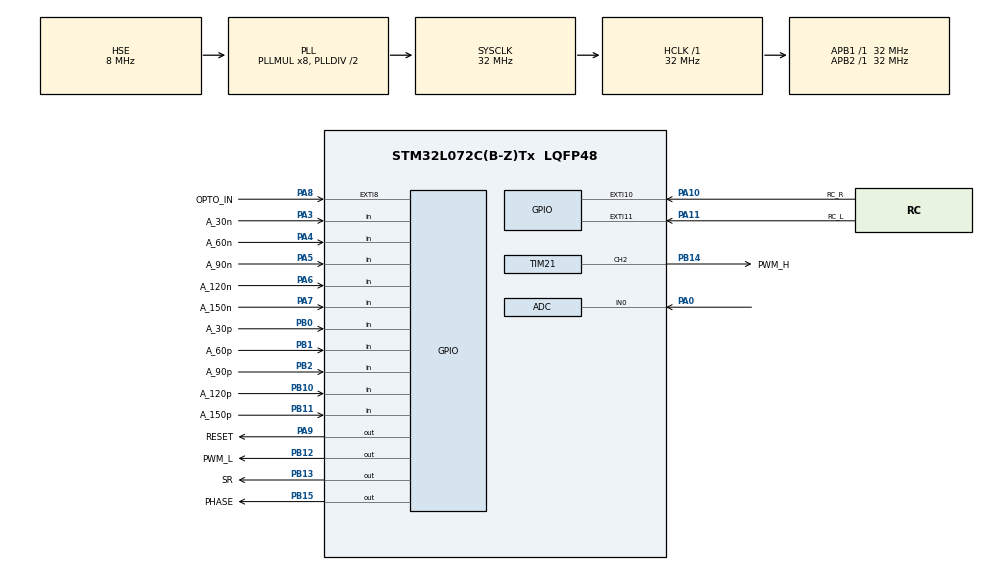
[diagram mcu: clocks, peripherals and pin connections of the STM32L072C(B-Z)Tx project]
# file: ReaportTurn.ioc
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Mcu.Family=STM32L0
PH0-OSC_IN.Signal=RCC_OSC_IN
Dma.ADC.0.Mode=DMA_CIRCULAR
PB10.GPIO_PuPd=GPIO_PULLDOWN
PB14.GPIO_Label=PWM_H
PA3.GPIO_PuPd=GPIO_PULLDOWN
Dma.ADC.0.Priority=DMA_PRIORITY_LOW
PB0.GPIO_Label=A_30p
PA6.GPIO_Label=A_120n
PB11.GPIO_PuPd=GPIO_PULLDOWN
PB13.GPIO_Label=SR
PB11.Signal=GPIO_Input
PB13.Signal=GPIO_Output
PB15.Signal=GPIO_Output
RCC.SYSCLKSource=RCC_SYSCLKSOURCE_PLLCLK
ProjectManager.StackSize=0x400
VP_TIM7_VS_ClockSourceINT.Mode=Enable_Timer
ADC.DiscontinuousConvMode=ENABLE
TIM21.Period=99
Dma.ADC.0.PeriphInc=DMA_PINC_DISABLE
PB1.GPIO_PuPd=GPIO_PULLDOWN
ADC.Ratio=ADC_OVERSAMPLING_RATIO_256
TIM21.Channel-PWM\ Generation2\ CH2=TIM_CHANNEL_2
RCC.HCLKFreq_Value=32000000
RCC.APB2TimFreq_Value=32000000
TIM7.Period=1999
SH.S_TIM21_CH2.0=TIM21_CH2,PWM Generation2 CH2
RCC.AHBFreq_Value=32000000
PH0-OSC_IN.Mode=HSE-External-Oscillator
Dma.ADC.0.Direction=DMA_PERIPH_TO_MEMORY
ADC.SamplingTime=ADC_SAMPLETIME_160CYCLES_5
RCC.HSE_VALUE=8000000
PA4.GPIO_PuPd=GPIO_PULLDOWN
PB2.Signal=GPIO_Input
RCC.PLLMUL=RCC_PLLMUL_8
PB12.GPIO_Label=PWM_L
PA6.GPIO_PuPd=GPIO_PULLDOWN
PA14.Mode=Serial_Wire
PA5.GPIO_PuPd=GPIO_PULLDOWN
PB1.GPIO_Label=A_60p
PA10.GPIO_Label=RC_R
PA0.Mode=IN0
PA8.Signal=GPXTI8
TIM6.Period=999
ADC.RightBitShift=ADC_RIGHTBITSHIFT_8
PB2.GPIO_PuPd=GPIO_PULLDOWN
PA0.Signal=ADC_IN0
Dma.ADC.0.MemInc=DMA_MINC_ENABLE
PH1-OSC_OUT.Mode=HSE-External-Oscillator
Mcu.Package=LQFP48
PB1.Signal=GPIO_Input
PA6.Signal=GPIO_Input
PA8.GPIO_ModeDefaultEXTI=GPIO_MODE_IT_FALLING
PA10.GPIO_ModeDefaultEXTI=GPIO_MODE_IT_FALLING
Dma.ADC.0.Instance=DMA1_Channel1
PA10.Signal=GPXTI10
Dma.ADC.0.MemDataAlignment=DMA_MDATAALIGN_HALFWORD
RCC.APB1TimFreq_Value=32000000
Dma.Request0=ADC
PA4.GPIO_Label=A_60n
ADC.ExternalTrigConv=ADC_EXTERNALTRIGCONV_T6_TRGO
NVIC.TIM7_IRQn=true\:2\:0\:true\:false\:true\:true\:true
NVIC.EXTI4_15_IRQn=true\:3\:0\:true\:false\:true\:true\:true
RCC.HSI48_VALUE=48000000
PA3.Signal=GPIO_Input
RCC.MSI_VALUE=2097000
RCC.PLLSourceVirtual=RCC_PLLSOURCE_HSE
PA9.GPIO_Label=RESET
TIM6.Prescaler=31
VP_TIM6_VS_ClockSourceINT.Mode=Enable_Timer
PB11.GPIO_Label=A_150p
PA11.GPIO_Label=RC_L
Dma.ADC.0.PeriphDataAlignment=DMA_PDATAALIGN_HALFWORD
PA13.Signal=SYS_SWDIO
RCC.HSI16_VALUE=16000000
PA8.GPIO_Label=OPTO_IN
ProjectManager.TargetToolchain=STM32CubeIDE
PB10.GPIO_Label=A_120p
PA9.Signal=GPIO_Output
ADC.OversamplingMode=ENABLE
RCC.LSE_VALUE=32768
PA7.GPIO_PuPd=GPIO_PULLDOWN
PB10.Signal=GPIO_Input
PB14.Signal=S_TIM21_CH2
PA5.Signal=GPIO_Input
ADC.DMAContinuousRequests=ENABLE
TIM7.Prescaler=31
board=custom
RCC.VCOOutputFreq_Value=64000000
RCC.APB2Freq_Value=32000000
VP_TIM21_VS_ClockSourceINT.Mode=Internal
PB15.GPIO_Label=PHASE
TIM21.Prescaler=15
TIM6.TIM_MasterOutputTrigger=TIM_TRGO_UPDATE
PH1-OSC_OUT.Signal=RCC_OSC_OUT
PA13.Mode=Serial_Wire
Mcu.Name=STM32L072C(B-Z)Tx
ADC.Overrun=ADC_OVR_DATA_OVERWRITTEN
PA4.Signal=GPIO_Input
RCC.SYSCLKFreq_VALUE=32000000
PA7.GPIO_Label=A_150n
PA5.GPIO_Label=A_90n
PA11.Signal=GPXTI11
PA14.Signal=SYS_SWCLK
PB2.GPIO_Label=A_90p
ProjectManager.HeapSize=0x200
RCC.HSI_VALUE=16000000
NVIC.DMA1_Channel1_IRQn=true\:3\:0\:true\:false\:true\:false\:true
PA11.GPIO_ModeDefaultEXTI=GPIO_MODE_IT_FALLING
RCC.APB1Freq_Value=32000000
PB0.Signal=GPIO_Input
PB12.Signal=GPIO_Output
PB0.GPIO_PuPd=GPIO_PULLDOWN
PA3.GPIO_Label=A_30n
PA7.Signal=GPIO_Input

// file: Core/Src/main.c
/* USER CODE BEGIN Header */
/**
 ******************************************************************************
 * @file           : main.c
 * @brief          : Main program body
 ******************************************************************************
 * @attention
 *
 * <h2><center>&copy; Copyright (c) 2020 STMicroelectronics.
 * All rights reserved.</center></h2>
 *
 * This software component is licensed by ST under BSD 3-Clause license,
 * the "License"; You may not use this file except in compliance with the
 * License. You may obtain a copy of the License at:
 *                        opensource.org/licenses/BSD-3-Clause
 *
 ******************************************************************************
 */
/* USER CODE END Header */
#include "main.h"
#include "adc.h"
#include "dma.h"
#include "tim.h"
#include "gpio.h"

/* USER CODE BEGIN Includes */
#include "maincpp.h"
/* USER CODE END Includes */

void SystemClock_Config(void);

int main(void)
{

  /* MCU Configuration--------------------------------------------------------*/

  /* Reset of all peripherals, Initializes the Flash interface and the Systick. */
  HAL_Init();

  /* Configure the system clock */
  SystemClock_Config();

  /* Initialize all configured peripherals */
  MX_GPIO_Init();
  MX_DMA_Init();
  MX_ADC_Init();
  MX_TIM6_Init();
  MX_TIM21_Init();
  MX_TIM7_Init();

  /* Infinite loop */
			while (1)
			{

    /* USER CODE BEGIN 3 */
						maincpp( );

			}
  /* USER CODE END 3 */
}

void SystemClock_Config(void)
{
  RCC_OscInitTypeDef RCC_OscInitStruct = {0};
  RCC_ClkInitTypeDef RCC_ClkInitStruct = {0};

  /** Configure the main internal regulator output voltage
  */
  __HAL_PWR_VOLTAGESCALING_CONFIG(PWR_REGULATOR_VOLTAGE_SCALE1);
  /** Initializes the RCC Oscillators according to the specified parameters
  * in the RCC_OscInitTypeDef structure.
  */
  RCC_OscInitStruct.OscillatorType = RCC_OSCILLATORTYPE_HSE;
  RCC_OscInitStruct.HSEState = RCC_HSE_ON;
  RCC_OscInitStruct.PLL.PLLState = RCC_PLL_ON;
  RCC_OscInitStruct.PLL.PLLSource = RCC_PLLSOURCE_HSE;
  RCC_OscInitStruct.PLL.PLLMUL = RCC_PLLMUL_8;
  RCC_OscInitStruct.PLL.PLLDIV = RCC_PLLDIV_2;
  if (HAL_RCC_OscConfig(&RCC_OscInitStruct) != HAL_OK)
  {
    Error_Handler();
  }
  /** Initializes the CPU, AHB and APB buses clocks
  */
  RCC_ClkInitStruct.ClockType = RCC_CLOCKTYPE_HCLK|RCC_CLOCKTYPE_SYSCLK
                              |RCC_CLOCKTYPE_PCLK1|RCC_CLOCKTYPE_PCLK2;
  RCC_ClkInitStruct.SYSCLKSource = RCC_SYSCLKSOURCE_PLLCLK;
  RCC_ClkInitStruct.AHBCLKDivider = RCC_SYSCLK_DIV1;
  RCC_ClkInitStruct.APB1CLKDivider = RCC_HCLK_DIV1;
  RCC_ClkInitStruct.APB2CLKDivider = RCC_HCLK_DIV1;

  if (HAL_RCC_ClockConfig(&RCC_ClkInitStruct, FLASH_LATENCY_1) != HAL_OK)
  {
    Error_Handler();
  }
}

void Error_Handler(void)
{
  /* USER CODE BEGIN Error_Handler_Debug */
			/* User can add his own implementation to report the HAL error return state */
			__disable_irq( );
			while (1)
			{

			}
  /* USER CODE END Error_Handler_Debug */
}

/************************ (C) COPYRIGHT STMicroelectronics *****END OF FILE****/
